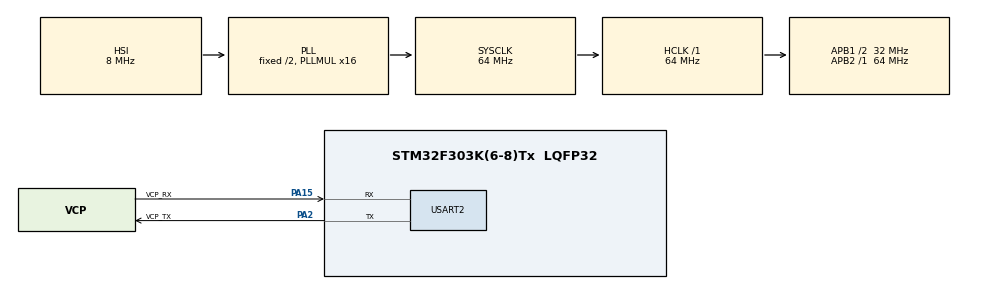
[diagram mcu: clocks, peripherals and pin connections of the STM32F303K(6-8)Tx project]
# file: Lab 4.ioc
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Mcu.Family=STM32F3
Mcu.Name=STM32F303K(6-8)Tx
Mcu.Package=LQFP32
NVIC.PriorityGroup=NVIC_PRIORITYGROUP_4
PA13.GPIO_Label=SWDIO
PA13.Mode=Serial_Wire
PA13.Signal=SYS_JTMS-SWDIO
PA14.GPIO_Label=SWCLK
PA14.Mode=Serial_Wire
PA14.Signal=SYS_JTCK-SWCLK
PA15.GPIO_Label=VCP_RX
PA15.Mode=Asynchronous
PA15.Signal=USART2_RX
PA2.GPIO_Label=VCP_TX
PA2.Mode=Asynchronous
PA2.Signal=USART2_TX
PF0\ /\ OSC_IN.GPIO_Label=MCO
PF0\ /\ OSC_IN.Mode=HSE-External-Clock-Source
PF0\ /\ OSC_IN.Signal=RCC_OSC_IN
ProjectManager.HeapSize=0x200
ProjectManager.StackSize=0x400
ProjectManager.TargetToolchain=STM32CubeIDE
RCC.AHBFreq_Value=64000000
RCC.APB1CLKDivider=RCC_HCLK_DIV2
RCC.APB1Freq_Value=32000000
RCC.APB1TimFreq_Value=64000000
RCC.APB2Freq_Value=64000000
RCC.APB2TimFreq_Value=64000000
RCC.CortexFreq_Value=64000000
RCC.HCLKFreq_Value=64000000
RCC.HSE_VALUE=8000000
RCC.HSI_VALUE=8000000
RCC.PLLMUL=RCC_PLL_MUL16
RCC.SYSCLKFreq_VALUE=64000000
RCC.SYSCLKSourceVirtual=RCC_SYSCLKSOURCE_PLLCLK
USART2.VirtualMode-Asynchronous=VM_ASYNC
board=NUCLEO-F303K8

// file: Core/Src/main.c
/* USER CODE BEGIN Header */
/**
  ******************************************************************************
  * @file           : main.c
  * @brief          : Main program body
  ******************************************************************************
  * @attention
  *
  * Copyright (c) 2023 STMicroelectronics.
  * All rights reserved.
  *
  * This software is licensed under terms that can be found in the LICENSE file
  * in the root directory of this software component.
  * If no LICENSE file comes with this software, it is provided AS-IS.
  *
  ******************************************************************************
  */
/* USER CODE END Header */
#include "main.h"
#define ARR_MAX 6399
#define _1surduty 0.01
float inc = 0;

/* USER CODE BEGIN Includes */
void setup()
{
	//1 - pin configuration: // alternate config 1 for PA0
	// GPIO setup
	RCC->AHBENR |= RCC_AHBENR_GPIOAEN_Msk; //GPIOA enable

	//set PA0 as alternate function
	GPIOA->MODER &= ~(0x03<<0);
	GPIOA->MODER |= 0x2<<0; //set as alternate function
	//or GPIOA->MODER |= 0x1<<1;

	//set alternate function
	GPIOA-> AFR[0] &= ~(0x0F); //reset
	GPIOA-> AFR[0] |= 0x01<<0;   // "0001=AF1 TIM 2 uses AF1"

	//2 - Timer configuration use TIM2 @ 10KHz

	//Enable clock for port B. IIM 2 setup
	RCC->AHBENR |= (0x01<<18);  //GPIOB enabled
	__asm ("nop");

	//Reset Peripheral
	RCC-> APB1RSTR |= (0x01<<0);
	RCC-> APB1RSTR &= ~(0x01<<0);
	__asm ("nop");

	//setting 10KHz for TIM2
	TIM2->PSC = 0;         //prescaler tick@ 10us
	TIM2->ARR = 6400-1;       //auto-reload: counts 100 ticks

	//3 - PWM Configuration:

	TIM2->CCMR1 &=~(0x03<<0); //Channel 1 as output capture mode
	TIM2->CCMR1 &= ~(0x1007); //reset register
	TIM2->CCMR1 |= 6 << 4; //output PWM mode 1 "0110"
	TIM2->CCMR1 |= 1<<3;//pre-load register, update during event, 1<<11
	TIM2->CR1 &= ~(7<<4); //mode 1 // edge aligned mode plus direction =0
	TIM2->CR1 &= ~(1<<3); //counter stops or continue at next overflow
	TIM2->CCER |= 1; //enable channel 1
	TIM2->CR1 |=1 ; //config reg : enable, 1<<0
	TIM2->CCR1 = 1600; //25% of ARR

	//Enable Interrupt

	TIM2->DIER |= 0x1<<0;   //Update interupt flag when it overflow
	NVIC_EnableIRQ(TIM2_IRQn);  // TIM2 with priority 28 for the interrupt handler
	}
	void TIM2_IRQHandler()

	{

		TIM2->SR &= ~TIM_SR_UIF;//reset the update
		inc+=0.00001;
		if(inc>=1)
		{
			inc=0;
		}
		TIM2->CCR1=(unsigned short int)(ARR_MAX*inc);
		}

/* USER CODE END Includes */

UART_HandleTypeDef huart2;

void SystemClock_Config(void);
static void MX_GPIO_Init(void);
static void MX_USART2_UART_Init(void);

int main(void)
{
  /* USER CODE BEGIN 1 */
setup();
  /* USER CODE END 1 */

  /* MCU Configuration--------------------------------------------------------*/

  /* Reset of all peripherals, Initializes the Flash interface and the Systick. */
  HAL_Init();

  /* Configure the system clock */
  SystemClock_Config();

  /* Initialize all configured peripherals */
  MX_GPIO_Init();
  MX_USART2_UART_Init();

  /* Infinite loop */
  while (1)
  {

  }
}

void SystemClock_Config(void)
{
  RCC_OscInitTypeDef RCC_OscInitStruct = {0};
  RCC_ClkInitTypeDef RCC_ClkInitStruct = {0};

  /** Initializes the RCC Oscillators according to the specified parameters
  * in the RCC_OscInitTypeDef structure.
  */
  RCC_OscInitStruct.OscillatorType = RCC_OSCILLATORTYPE_HSI;
  RCC_OscInitStruct.HSIState = RCC_HSI_ON;
  RCC_OscInitStruct.HSICalibrationValue = RCC_HSICALIBRATION_DEFAULT;
  RCC_OscInitStruct.PLL.PLLState = RCC_PLL_ON;
  RCC_OscInitStruct.PLL.PLLSource = RCC_PLLSOURCE_HSI;
  RCC_OscInitStruct.PLL.PLLMUL = RCC_PLL_MUL16;
  if (HAL_RCC_OscConfig(&RCC_OscInitStruct) != HAL_OK)
  {
    Error_Handler();
  }

  /** Initializes the CPU, AHB and APB buses clocks
  */
  RCC_ClkInitStruct.ClockType = RCC_CLOCKTYPE_HCLK|RCC_CLOCKTYPE_SYSCLK
                              |RCC_CLOCKTYPE_PCLK1|RCC_CLOCKTYPE_PCLK2;
  RCC_ClkInitStruct.SYSCLKSource = RCC_SYSCLKSOURCE_PLLCLK;
  RCC_ClkInitStruct.AHBCLKDivider = RCC_SYSCLK_DIV1;
  RCC_ClkInitStruct.APB1CLKDivider = RCC_HCLK_DIV2;
  RCC_ClkInitStruct.APB2CLKDivider = RCC_HCLK_DIV1;

  if (HAL_RCC_ClockConfig(&RCC_ClkInitStruct, FLASH_LATENCY_2) != HAL_OK)
  {
    Error_Handler();
  }
}

static void MX_USART2_UART_Init(void)
{

  huart2.Instance = USART2;
  huart2.Init.BaudRate = 38400;
  huart2.Init.WordLength = UART_WORDLENGTH_8B;
  huart2.Init.StopBits = UART_STOPBITS_1;
  huart2.Init.Parity = UART_PARITY_NONE;
  huart2.Init.Mode = UART_MODE_TX_RX;
  huart2.Init.HwFlowCtl = UART_HWCONTROL_NONE;
  huart2.Init.OverSampling = UART_OVERSAMPLING_16;
  huart2.Init.OneBitSampling = UART_ONE_BIT_SAMPLE_DISABLE;
  huart2.AdvancedInit.AdvFeatureInit = UART_ADVFEATURE_NO_INIT;
  if (HAL_UART_Init(&huart2) != HAL_OK)
  {
    Error_Handler();
  }

}

static void MX_GPIO_Init(void)
{

  /* GPIO Ports Clock Enable */
  __HAL_RCC_GPIOF_CLK_ENABLE();
  __HAL_RCC_GPIOA_CLK_ENABLE();

}

void Error_Handler(void)
{
  __disable_irq();
  while (1)
  {
  }
}
